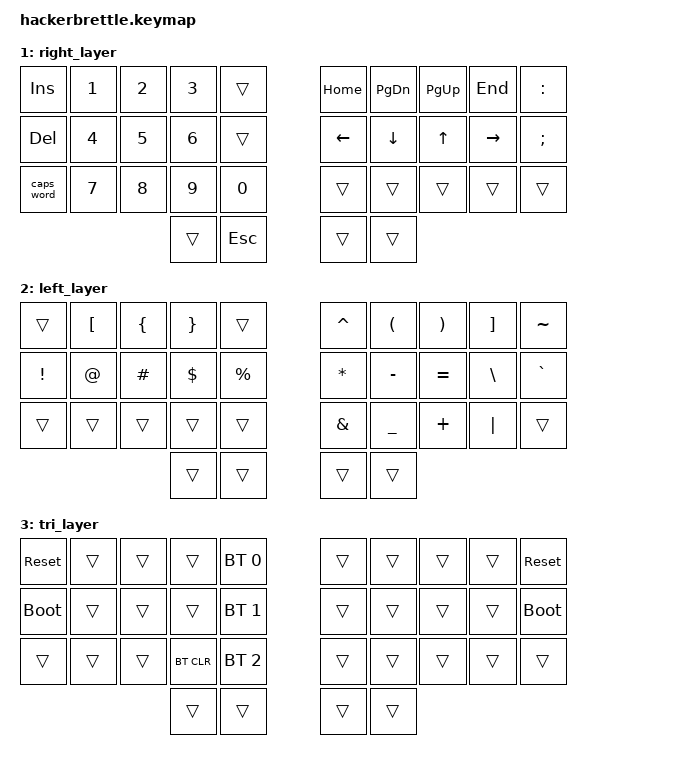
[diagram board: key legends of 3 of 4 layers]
// Copyright (c) 2022 The ZMK Contributors
// SPDX-License-Identifier: MIT

#include <behaviors.dtsi>
#include <dt-bindings/zmk/keys.h>
#include <dt-bindings/zmk/bt.h>

// Home row mods macro
#define HRML(k1,k2,k3,k4) &ht LGUI k1  &ht LALT k2  &ht LCTRL k3  &ht LSHFT k4
#define HRMR(k1,k2,k3,k4) &ht RSHFT k1  &ht RCTRL k2  &ht RALT k3  &ht RGUI k4

#define BASE 0
#define NUMSYM 1
#define NAVFN 2
#define SYSTEM 3
#define CMD 4

/ {
    behaviors {
        ht: hold_tap {
            compatible = "zmk,behavior-hold-tap";
            #binding-cells = <2>;
            flavor = "tap-preferred";
            tapping-term-ms = <300>;
            quick-tap-ms = <150>;
            require-prior-idle-ms = <100>;
            bindings = <&kp>, <&kp>;
        };
    };

    conditional_layers {
        compatible = "zmk,conditional-layers";
        tri_layer {
            if-layers = <NUMSYM NAVFN>;
            then-layer = <SYSTEM>;
        };
    };
    
    macros {
        nav_cmd: nav_cmd {
            compatible = "zmk,behavior-macro";
            #binding-cells = <0>;
            bindings
                = <&macro_press &lt NAVFN>
                , <&macro_tap &sk CMD>
                , <&madro_release &lt NAVFN>
                ;
        }
    }

    keymap {
        compatible = "zmk,keymap";
        default_layer {
            bindings = <
 //             ┌─────┐                             ┌─────┐
 //       ┌─────┤f    │                             │u    ├─────┐
 // ┌─────┤w    │     ├─────┬─────┐     ┌─────┬─────┤     │y    ├─────┐
 // │q    │     ├─────┤p    │b    │     │j    │l    ├─────┤     │- _  │
 // │     ├─────┤s    │     │     │     │     │     │e    ├─────┤     │
 // ├─────┤r    │     ├─────┼─────┤     ├─────┼─────┤     │i    ├─────┤
 // │a    │     ├─────┤t    │g    │     │m    │n    ├─────┤     │o    │
 // │     ├─────┤c    │     │     │     │     │     │, ?  ├─────┤     │
 // ├─────┤x    │     ├─────┼─────┤     ├─────┼─────┤     │. !  ├─────┤
 // │z    │     ├─────┤d    │v    │     │k    │h    ├─────┤     │' "  │
 // │     ├─────┘     │     │     │     │     │     │     └─────┤     │
 // └─────┘           └─────┴─────┘     └─────┴─────┘           └─────┘
 //                   ┌─────┬─────┐     ┌─────┬─────┐
 //                   │space│lead │     │lead │cmd  │
 //                   │shift│numsy│     │numsy│navfn│
 //                   └─────┴─────┘     └─────┴─────┘

            &kp Q      &kp W      &kp F      &kp P      &kp B          &kp J      &kp L      &kp U      &kp Y      &kp P
            &kp A      &kp R      &kp S      &kp T      &kp G          &kp M      &kp N      &kp E      &kp I      &kp O
            HRML(Z,    X,         C,         D)         &kp V          &kp K      HRMR(H,    COMMA,     DOT,       FSLH)
                                      &mt LSHFT SPACE   &lt NUMSYM CAPS     &lt NUMSYM CAPS  &lt NAVFN PRIR
            >;
        };

        right_layer {
 //             ┌─────┐                             ┌─────┐
 //       ┌─────┤8    │                             │3    ├─────┐
 // ┌─────┤7    │     ├─────┬─────┐     ┌─────┬─────┤     │4    ├─────┐
 // │6    │     ├─────┤9    │0    │     │1    │2    ├─────┤     │5    │
 // │     ├─────┤= \  │     │     │     │     │     │[    ├─────┤     │
 // ├─────┤@    │     ├─────┼─────┤     ├─────┼─────┤     │{    ├─────┤
 // │~    │     ├─────┤* |  │+ /  │     │:    │(    ├─────┤     │<    │
 // │     ├─────┤^    │     │     │     │     │     │] ,  ├─────┤     │
 // ├─────┤%    │     ├─────┼─────┤     ├─────┼─────┤     │} .  ├─────┤
 // │$    │     ├─────┤#    │&    │     │;    │)    ├─────┤     │>    │
 // │     ├─────┘     │     │     │     │     │     │     └─────┤     │
 // └─────┘           └─────┴─────┘     └─────┴─────┘           └─────┘
 //                   ┌─────┬─────┐     ┌─────┬─────┐
 //                   │space│lead │     │lead │cmd  │
 //                   │shift│numsy│     │numsy│navfn│
 //                   └─────┴─────┘     └─────┴─────┘
            bindings = <
            &kp INS    &kp N1     &kp N2     &kp N3     &trans         &kp HOME   &kp PG_DN  &kp PG_UP  &kp END    &kp COLON
            &kp DEL    &kp N4     &kp N5     &kp N6     &trans         &kp LEFT   &kp DOWN   &kp UP   &kp RIGHT   &kp SEMI
           &caps_word  &kp N7     &kp N8     &kp N9     &kp N0         &trans     &trans     &trans     &trans     &trans
                                             &trans     &kp ESC        &trans     &trans
            >;
        };

        left_layer {
 //             ┌─────┐                             ┌─────┐
 //       ┌─────┤F3   │                             │↑    ├─────┐
 // ┌─────┤F2   │     ├─────┬─────┐     ┌─────┬─────┤     │PgDwn├─────┐
 // │F1   │     ├─────┤F4   │F5   │     │Top  │PgUp ├─────┤     │Bottm│
 // │     ├─────┤F8   │     │     │     │     │     │↓    ├─────┤     │
 // ├─────┤F7   │     ├─────┼─────┤     ├─────┼─────┤     │→    ├─────┤
 // │F6   │     ├─────┤F9   │F10  │     │Home │←    ├─────┤     │End  │
 // │     ├─────┤CtrlC│     │     │     │     │     │SelLn├─────┤     │
 // ├─────┤F12  │     ├─────┼─────┤     ├─────┼─────┤     │WrdRg├─────┤
 // │F11  │     ├─────┤CtrlX│CtrlV│     │SelWL│WrdLf├─────┤     │SelWR│
 // │     ├─────┘     │     │     │     │     │     │     └─────┤     │
 // └─────┘           └─────┴─────┘     └─────┴─────┘           └─────┘
 //                   ┌─────┬─────┐     ┌─────┬─────┐
 //                   │space│lead │     │lead │cmd  │
 //                   │shift│numsy│     │numsy│navfn│
 //                   └─────┴─────┘     └─────┴─────┘
            bindings = <
            &trans     &kp LBKT   &kp LBRC   &kp RBRC   &trans         &kp CARET  &kp LPAR   &kp RPAR   &kp RBKT   &kp TILDE
            &kp EXCL   &kp AT     &kp HASH   &kp DLLR   &kp PRCNT      &kp ASTRK  &kp MINUS  &kp EQUAL  &kp BSLH   &kp GRAVE
            &trans     &trans     &trans     &trans     &trans         &kp AMPS   &kp UNDER  &kp PLUS   &kp PIPE   &trans
                                             &trans     &trans         &trans     &trans
            >;
        };

        tri_layer {
 //             ┌─────┐                             ┌─────┐
 //       ┌─────┤play │                             │mouse├─────┐
 // ┌─────┤track│pause├─────┬─────┐     ┌─────┬─────┤up   │msWhl├─────┐
 // │Boot │prev ├─────┤track│vol  │     │msWhl│msWhl├─────┤right│mouse│
 // │     ├─────┤stop │next │up   │     │up   │left │mouse├─────┤acc2 │
 // ├─────┤RGB  │     ├─────┼─────┤     ├─────┼─────┤down │mouse├─────┤
 // │RGB  │Lum+ ├─────┤RGB  │vol  │     │msWhl│mouse├─────┤right│mouse│
 // │Sat+ ├─────┤RGB  │Hue+ │down │     │down │left │mouse├─────┤acc1 │
 // ├─────┤RGB  │Mode ├─────┼─────┤     ├─────┼─────┤btn3 │mouse├─────┤
 // │RGB  │Lum- ├─────┤RGB  │vol  │     │RGB  │mouse├─────┤btn2 │mouse│
 // │Sat- ├─────┘     │Hue- │mute │     │OnOff│btn1 │     └─────┤acc0 │
 // └─────┘           └─────┴─────┘     └─────┴─────┘           └─────┘
 //                   ┌─────┬─────┐     ┌─────┬─────┐
 //                   │space│lead │     │lead │cmd  │
 //                   │shift│numsy│     │numsy│navfn│
 //                   └─────┴─────┘     └─────┴─────┘
            bindings = <
           &sys_reset  &trans     &trans     &trans    &bt BT_SEL 0    &trans     &trans     &trans     &trans    &sys_reset
          &bootloader  &trans     &trans     &trans    &bt BT_SEL 1    &trans     &trans     &trans     &trans    &bootloader
            &trans     &trans     &trans    &bt BT_CLR &bt BT_SEL 2    &trans     &trans     &trans     &trans     &trans
                                             &trans     &trans         &trans     &trans
            >;
        };
    };
};
